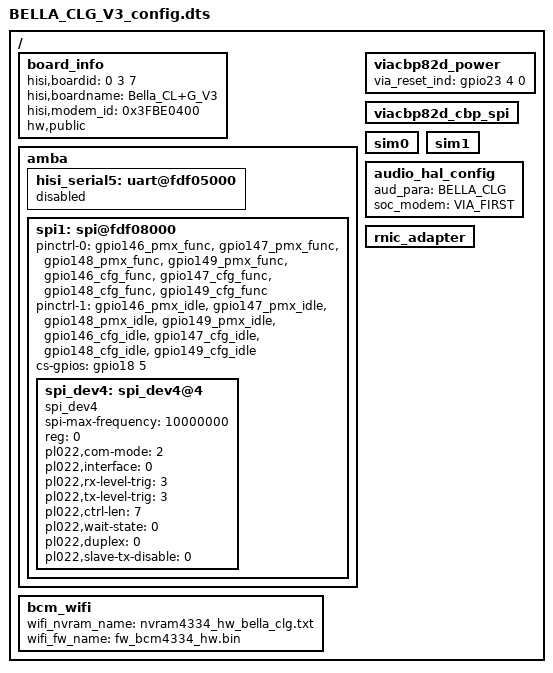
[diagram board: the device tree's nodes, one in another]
/*
 * Hisilicon Ltd.
 *
 * A15x4 A7x4
 *
 * It is only a demo for hisilicon hi3630 board. You show change the
 * address of each node according to datasheet.
 */

/dts-v1/;

/include/ "huawei_ext_modem.dtsi"
/include/ "hisi_sim_hotplug.dtsi"

/include/ "BELLA_ULG_V3_config.dtsi"
/include/ "hisi_3630_pin_BELLA_CLG_V3.dtsi"
/include/ "hisi_3630_modem_BELLA_CLG_V3.dtsi"
/ {
	board_info: board_info {
		hisi,boardid = <0 3 7>;
		hisi,boardname = "Bella_CL+G_V3";
		hisi,modem_id = <0x3FBE0400>;
		hw,public;
	};
	amba {
		hisi_serial5: uart@fdf05000 {
			status = "disabled";
		};

		spi1: spi@fdf08000 {
		status = "ok";
		pinctrl-names = "default", "idle";
		pinctrl-0 = <&gpio146_pmx_func &gpio147_pmx_func &gpio148_pmx_func &gpio149_pmx_func
				 &gpio146_cfg_func &gpio147_cfg_func &gpio148_cfg_func &gpio149_cfg_func>;
		pinctrl-1 = <&gpio146_pmx_idle &gpio147_pmx_idle &gpio148_pmx_idle &gpio149_pmx_idle
				 &gpio146_cfg_idle &gpio147_cfg_idle &gpio148_cfg_idle &gpio149_cfg_idle>;
		#address-cells = <1>;
		#size-cells = <0>;
		cs-gpios = <&gpio18 5 0>;
		spi_dev4: spi_dev4@4 {
			compatible = "spi_dev4";
			spi-max-frequency = <10000000>;
			reg = <0>;
			pl022,com-mode = <2>; //2
			pl022,interface = <0>;
			pl022,rx-level-trig = <3>;
			pl022,tx-level-trig = <3>;
			pl022,ctrl-len = <7>;
			pl022,wait-state = <0>;
			pl022,duplex = <0>;
			pl022,slave-tx-disable = <0>;
			};
		};
	};
	viacbp82d_power:viacbp82d_power {\
		via_reset_ind = <&gpio23 4 0>;	      // modem reset notice AP, 188
		status = "ok";
	};
	viacbp82d_cbp_spi:viacbp82d_cbp_spi {
		status = "ok";
	};
	bcm_wifi {
		wifi_nvram_name = "nvram4334_hw_bella_clg.txt";
		wifi_fw_name = "fw_bcm4334_hw.bin";
		status = "ok";
	};
	sim0 {
		status = "ok";
	};
	sim1 {
		status = "ok";
	};
	audio_hal_config {
		aud_para = "BELLA_CLG";
		soc_modem = "VIA_FIRST";
	};

	rnic_adapter:rnic_adapter {
		status = "ok";
	};

};
